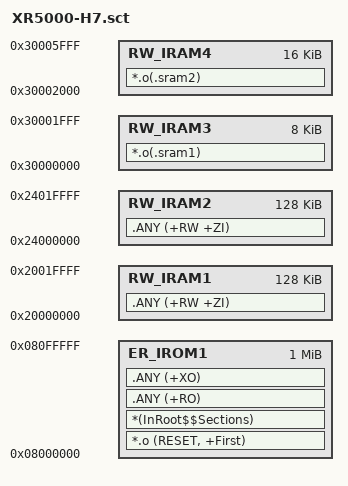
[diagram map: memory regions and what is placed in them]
; *************************************************************
; *** Scatter-Loading Description File generated by uVision ***
; *************************************************************

LR_IROM1 0x08000000 0x00100000  {    ; load region size_region
  ER_IROM1 0x08000000 0x00100000  {  ; load address = execution address
   *.o (RESET, +First)
   *(InRoot$$Sections)
   .ANY (+RO)
   .ANY (+XO)
  }
  RW_IRAM1 0x20000000 0x00020000  {  ; RW data
   .ANY (+RW +ZI)
  }
  RW_IRAM2 0x24000000 0x00020000  {
   .ANY (+RW +ZI)
  }
  ; new zone
  RW_IRAM3 0x30000000 0x00002000 {  ; SRAM1（D2域）
    *.o(.sram1)                      ; 将.sram1段的数据放在这里
  }
  ; new zone 2025/12/04 10:19
  RW_IRAM4 0x30002000 0x00004000 {  ; SRAM1（D2域）
    *.o(.sram2)                      ; 将.sram2段的数据放在这里
  }
}

; 内存区域名称 起始地址 长度 {
;     段名称 起始地址 长度 {
;         目标文件(*.o) 的段名
;     }
; }

; LR_IROM1：表示 加载区域（Load Region），即 Flash 的地址范围（0x08000000 开始，大小 0x00200000 = 2MB）
; ER_IROM1：表示 执行区域（Execution Region），即代码实际运行的地址（通常和 Flash 地址一致）
; *.o (RESET, +First)：把 Reset_Handler（启动代码）放在 Flash 的最前面（+First）。
; *(InRoot$$Sections)：包含 C 库初始化代码（如 __main）。
; .ANY (+RO)：所有 只读数据（代码、常量等） 都放在这里。

; RW_IRAM1：DTCM（Data Tightly Coupled Memory），地址 0x20000000，大小 0x00020000（128KB）
; .ANY (+RW +ZI)：所有 全局变量、静态变量、堆栈 默认放在这里（除非手动指定其他区域）。
; +RW = Read-Write（已初始化变量）
; +ZI = Zero-Initialized（未初始化变量，如 static int x;）

; RW_IRAM2：AXI-SRAM，地址 0x24000000，大小 0x00020000（128KB）。
; .ANY (+RW +ZI)：如果没有手动指定，部分变量可能会被编译器自动分配到这里。

; RW_IRAM3：D2 域的 SRAM1，地址 0x30000000，大小 0x00004000（16KB）。
; *.o(.sram1)：只有用 __attribute__((section(".sram1"))) 声明的变量 才会放在这里。

; *.o 是一个 通配符匹配规则，用于指定 哪些目标文件（.o文件）的哪些段（Section） 应该被放置到特定的内存区域
; *.o 表示 所有目标文件（即编译后生成的 .o 文件）
; 它可以匹配 工程中的所有 .o 文件，也可以结合段名（如 .sram1）进行更精细的控制

; 定义内存区域
; LR_IROM1 0x08000000 0x00200000 {    ; Flash区域
;  ER_IROM1 0x08000000 0x00200000 {  ; 代码和只读数据
;    *.o (RESET, +First)
;    *(InRoot$$Sections)
;    .ANY (+RO)
;  }
;  RW_IRAM1 0x20000000 0x00020000 {  ; DTCM（默认RAM）
;    .ANY (+RW +ZI)
;  }
;  RW_IRAM2 0x24000000 0x00020000 {  ; AXI-SRAM（D1域）
;    .ANY (+RW +ZI)
;  }
;  RW_IRAM3 0x30000000 0x00004000 {  ; SRAM1（D2域）
;    *.o(.sram1)                      ; 将.sram1段的数据放在这里
;  }
;}

